# cc13x2_cc26x2 register map
File version: 2.1
CPU: CM4 r0p1, little endian, MPU, FPU, 3 interrupt priority bits
Registers are 32-bit, read-write, reset 0x0 unless marked. A register's access mark holds for its fields unless they carry their own. Offsets are from the block's base; [hi:lo] are bit positions; {n}, {i} and the like mark numbered series; 'fields as' and 'values as' point back to an identical list.

## I2S0 — I2S Audio DMA module supporting formats I2S, LJF, RJF and DSP
Base 0x40021000
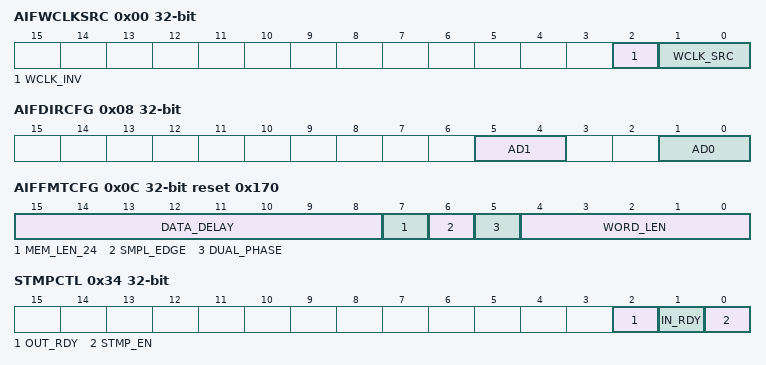
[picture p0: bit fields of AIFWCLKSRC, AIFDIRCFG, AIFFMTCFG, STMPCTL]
0x00 AIFWCLKSRC — WCLK Source Selection
  [2] WCLK_INV, [1:0] WCLK_SRC
0x04 AIFDMACFG — DMA Buffer Size Configuration
  [7:0] END_FRAME_IDX
0x08 AIFDIRCFG — Pin Direction
  [5:4] AD1, [1:0] AD0
0x0C AIFFMTCFG reset 0x170 — Serial Interface Format Configuration
  [15:8] DATA_DELAY, [7] MEM_LEN_24, [6] SMPL_EDGE, [5] DUAL_PHASE, [4:0] WORD_LEN
0x10 AIFWMASK0 reset 0x3 — Word Selection Bit Mask for Pin 0
  [7:0] MASK
0x14 AIFWMASK1 reset 0x3 — Word Selection Bit Mask for Pin 1
  [7:0] MASK
0x1C AIFPWMVALUE — Audio Interface PWM Debug Value
  [15:0] PULSE_WIDTH
0x20 AIFINPTRNEXT — DMA Input Buffer Next Pointer
  [31:0] PTR
0x24 AIFINPTR — DMA Input Buffer Current Pointer
  [31:0] PTR
0x28 AIFOUTPTRNEXT — DMA Output Buffer Next Pointer
  [31:0] PTR
0x2C AIFOUTPTR — DMA Output Buffer Current Pointer
  [31:0] PTR
0x34 STMPCTL — Samplestamp Generator Control Register
  [2] OUT_RDY, [1] IN_RDY, [0] STMP_EN
0x38 STMPXCNTCAPT0 ro — Captured XOSC Counter Value, Capture Channel 0
  [15:0] CAPT_VALUE
0x3C STMPXPER ro — XOSC Period Value
  [15:0] VALUE
0x40 STMPWCNTCAPT0 ro — Captured WCLK Counter Value, Capture Channel 0
  [15:0] CAPT_VALUE
0x44 STMPWPER — WCLK Counter Period Value
  [15:0] VALUE
0x48 STMPINTRIG — WCLK Counter Trigger Value for Input Pins
  [15:0] IN_START_WCNT
0x4C STMPOUTTRIG — WCLK Counter Trigger Value for Output Pins
  [15:0] OUT_START_WCNT
0x50 STMPWSET — WCLK Counter Set Operation
  [15:0] VALUE
0x54 STMPWADD — WCLK Counter Add Operation
  [15:0] VALUE_INC
0x58 STMPXPERMIN reset 0xFFFF — XOSC Minimum Period Value inimum Value of STMPXPER
  [15:0] VALUE
0x5C STMPWCNT ro — Current Value of WCNT
  [15:0] CURR_VALUE
0x60 STMPXCNT ro — Current Value of XCNT
  [15:0] CURR_VALUE
0x64 STMPXCNTCAPT1 ro — Internal. Only to be used through TI provided API.
  [15:0] CAPT_VALUE
0x68 STMPWCNTCAPT1 ro — Internal. Only to be used through TI provided API.
  [15:0] CAPT_VALUE
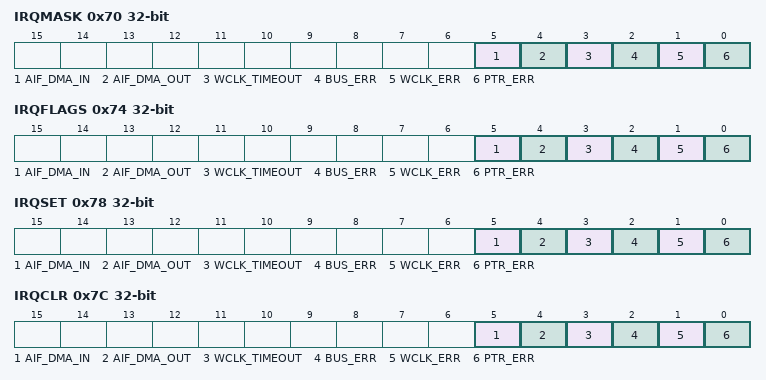
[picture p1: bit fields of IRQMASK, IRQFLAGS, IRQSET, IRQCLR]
0x70 IRQMASK — Interrupt Mask Register elects mask states of the flags in IRQFLAGS that contribute to the I2S_IRQ event.
  [5] AIF_DMA_IN, [4] AIF_DMA_OUT, [3] WCLK_TIMEOUT, [2] BUS_ERR, [1] WCLK_ERR, [0] PTR_ERR
0x74 IRQFLAGS ro — Raw Interrupt Status Register
  fields as IRQMASK
0x78 IRQSET wo — Interrupt Set Register
  fields as IRQMASK
0x7C IRQCLR wo — Interrupt Clear Register
  fields as IRQMASK

## IOC — IO Controller (IOC) - configures all the DIOs and resides in the MCU domain.
Base 0x40081000
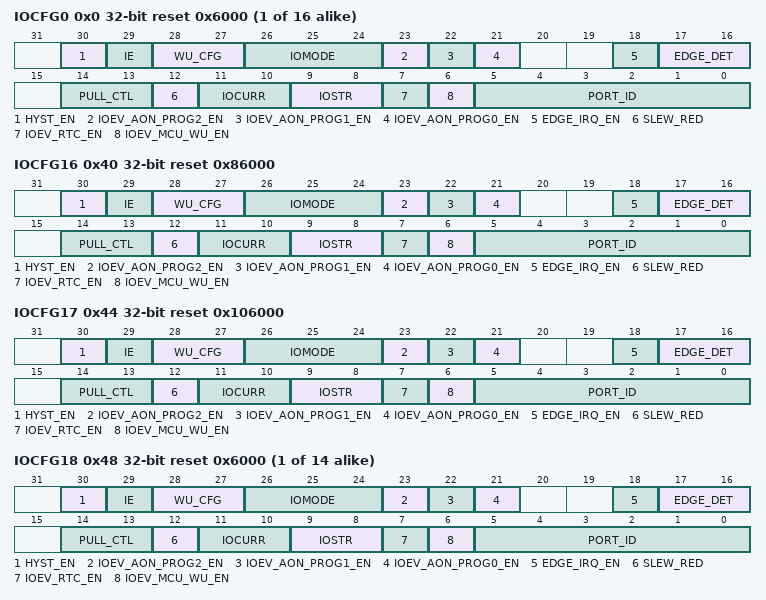
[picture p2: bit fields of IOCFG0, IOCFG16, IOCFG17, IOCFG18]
{0x0+4i} IOCFG{i} reset 0x6000 (i=0..15) — Configuration of DIO{i}
  [30] HYST_EN, [29] IE, [28:27] WU_CFG, [26:24] IOMODE, [23] IOEV_AON_PROG2_EN, [22] IOEV_AON_PROG1_EN, [21] IOEV_AON_PROG0_EN, [18] EDGE_IRQ_EN, [17:16] EDGE_DET, [14:13] PULL_CTL, [12] SLEW_RED, [11:10] IOCURR, [9:8] IOSTR, [7] IOEV_RTC_EN, [6] IOEV_MCU_WU_EN, [5:0] PORT_ID
0x40 IOCFG16 reset 0x86000 — Configuration of DIO16
  fields as IOCFG0
0x44 IOCFG17 reset 0x106000 — Configuration of DIO17
  fields as IOCFG0
{0x0+4i} IOCFG{i} reset 0x6000 (i=18..31) — Configuration of DIO{i}
  fields as IOCFG0

## SMPH — MCU Semaphore Module his module provides 32 binary semaphores. The state of a binary semaphore is either taken or available. semaphore does not implement any ownership attribute. Still, a semaphore can be used to handle mutual exclusion scenarios.
Base 0x40084000
{0x0+4i} SMPH{i} reset 0x1 (i=0..31) — MCU SEMAPHORE {i}
  [0] STAT read-clears
{0x800+4i} PEEK{i} ro reset 0x1 (i=0..31) — MCU SEMAPHORE {i} ALIAS
  [0] STAT

## SSI0 — Synchronous Serial Interface with master and slave capabilities
Base 0x40000000
Same registers: SSI1 0x40008000
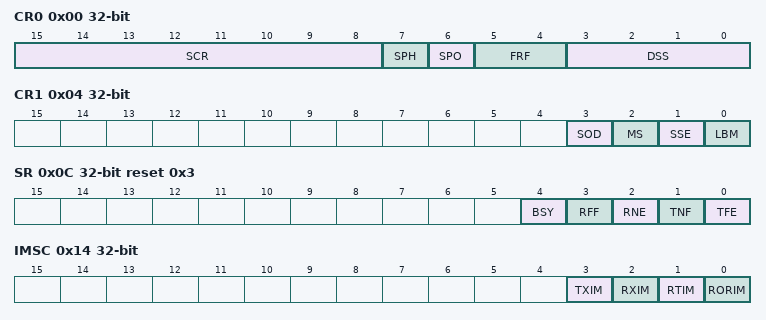
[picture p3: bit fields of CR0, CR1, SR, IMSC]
0x00 CR0 — Control 0
  [15:8] SCR, [7] SPH, [6] SPO, [5:4] FRF, [3:0] DSS
0x04 CR1 — Control 1
  [3] SOD, [2] MS, [1] SSE, [0] LBM
0x08 DR — Data 6-bits wide data register: hen read, the entry in the receive FIFO, pointed to by the current FIFO read pointer, is accessed. As data values are removed by the receive logic from the incoming data frame, they are placed into the entry in the receive FIFO, pointed to by the current FIFO write pointer. hen written, the entry in the transmit FIFO, pointed to by the write pointer, is written to. Data values are removed from the transmit FIFO one value at a time by the transmit logic. It is loaded into the transmit serial shifter, then serially shifted out onto the TXD output pin at the programmed bit rate. hen a data size of less than 16 bits is selected, the user must right-justify data written to the transmit FIFO. The transmit logic ignores the unused bits. Received data less than 16 bits is automatically right-justified in the receive buffer.
  [15:0] DATA
0x0C SR ro reset 0x3 — Status
  [4] BSY, [3] RFF, [2] RNE, [1] TNF, [0] TFE
0x10 CPSR — Clock Prescale
  [7:0] CPSDVSR
0x14 IMSC — Interrupt Mask Set and Clear
  [3] TXIM, [2] RXIM, [1] RTIM, [0] RORIM
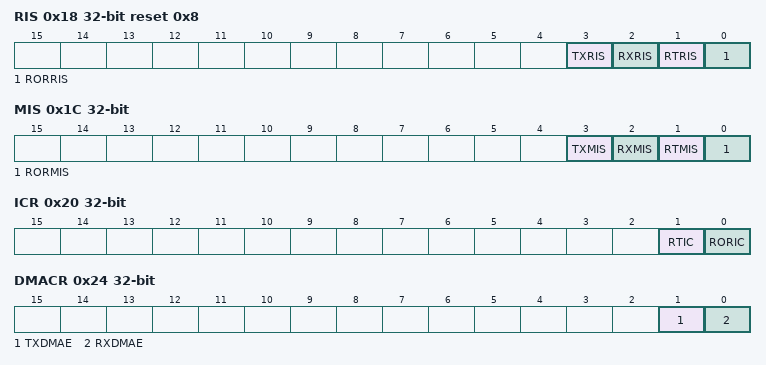
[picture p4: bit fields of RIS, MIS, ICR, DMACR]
0x18 RIS ro reset 0x8 — Raw Interrupt Status
  [3] TXRIS, [2] RXRIS, [1] RTRIS, [0] RORRIS
0x1C MIS ro — Masked Interrupt Status
  [3] TXMIS, [2] RXMIS, [1] RTMIS, [0] RORMIS
0x20 ICR wo — Interrupt Clear n a write of 1, the corresponding interrupt is cleared. A write of 0 has no effect.
  [1] RTIC, [0] RORIC
0x24 DMACR — DMA Control
  [1] TXDMAE, [0] RXDMAE
